VERSION ""

NS_ :

BS_:
BU_:
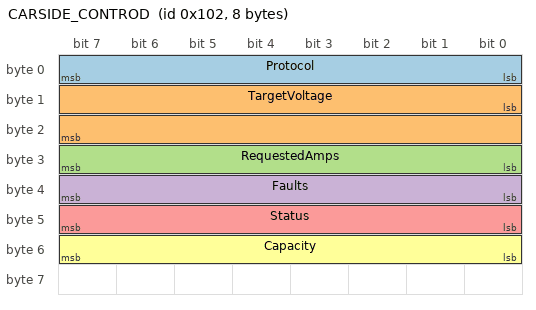
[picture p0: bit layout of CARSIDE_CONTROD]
BO_ 258 CARSIDE_CONTROD: 8 Vector__XXX
   SG_ Protocol : 0|8@1+ (1,0) [0|0] "" Vector__XXX
   SG_ TargetVoltage : 8|16@1+ (1,0) [0|0] "" Vector__XXX
   SG_ RequestedAmps : 24|8@1+ (1,0) [0|0] "" Vector__XXX
   SG_ Faults : 32|8@1+ (1,0) [0|0] "" Vector__XXX
   SG_ Status : 40|8@1+ (1,0) [0|0] "" Vector__XXX
   SG_ Capacity : 48|8@1+ (1,0) [0|0] "kWh" Vector__XXX

BO_ 256 CARSIDE_BATT: 8 Vector__XXX
   SG_ PackSize : 48|8@1+ (1,0) [0|0] "" Vector__XXX
   SG_ MaxVoltage : 32|16@1+ (1,0) [0|0] "" Vector__XXX

BO_ 257 CARSIDE_CHARGETIME: 8 Vector__XXX

BO_ 264 EVSE_PARAMS: 0 Vector__XXX
   SG_ AvailableVoltage : 8|16@1+ (1,0) [0|0] "" Vector__XXX
   SG_ AvailableCurrent : 24|8@1+ (1,0) [0|0] "" Vector__XXX
   SG_ ThresholdVoltage : 32|16@1+ (1,0) [0|0] "" Vector__XXX
   SG_ WeldCheckSupport : 0|8@1+ (1,0) [0|0] "" Vector__XXX

BO_ 265 EVSE_STATUS: 0 Vector__XXX
   SG_ Protocol : 0|8@1+ (1,0) [0|0] "" Vector__XXX
   SG_ PresentVoltage : 8|16@1+ (1,0) [0|0] "" Vector__XXX
   SG_ PresentCurrent : 24|8@1+ (1,0) [0|0] "" Vector__XXX
   SG_ Status : 40|8@1+ (1,0) [0|0] "" Vector__XXX

BA_DEF_ BO_ "GenMsgBackgroundColor" STRING ;
BA_DEF_ BO_ "GenMsgForegroundColor" STRING ;
BA_DEF_DEF_ "GenMsgBackgroundColor" "#ffffff";
BA_DEF_DEF_ "GenMsgForegroundColor" "#000000";
VAL_ 258 Protocol 1 "0.9_Chademo_Protocol";
VAL_ 258 Faults 1 "Over_Voltage" 2 "Under_Voltage" 4 "Current_Mismatch" 8 "Over_Temperature" 22 "Charger_Stop";
VAL_ 258 Status 1 "Charge" 2 "NotInPark" 4 "Malformed" 8 "ContactorOpen" 22 "ChargerStop";
VAL_ 265 Status 1 "Charge" 2 "Error" 3 "ConnectorLocked" 8 "Params_Mismatch" 22 "Battery_Error" 50 "Stopped";
